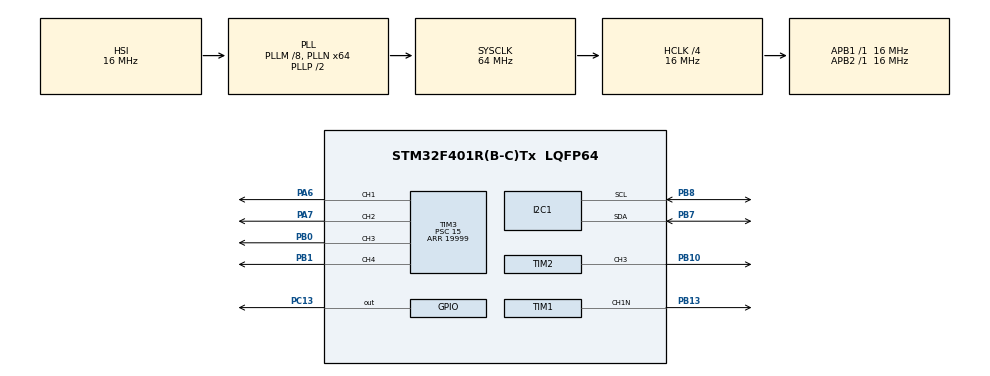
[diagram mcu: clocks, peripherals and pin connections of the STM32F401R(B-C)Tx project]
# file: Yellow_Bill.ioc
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I2C1.OwnAddress=8
Mcu.Family=STM32F4
Mcu.Name=STM32F401R(B-C)Tx
Mcu.Package=LQFP64
NVIC.I2C1_ER_IRQn=true\:0\:0\:false\:false\:true\:true\:true\:true
NVIC.I2C1_EV_IRQn=true\:0\:0\:false\:false\:true\:true\:true\:true
NVIC.PriorityGroup=NVIC_PRIORITYGROUP_4
PA13.Mode=Serial_Wire
PA13.Signal=SYS_JTMS-SWDIO
PA14.Mode=Serial_Wire
PA14.Signal=SYS_JTCK-SWCLK
PA6.Signal=S_TIM3_CH1
PA7.Signal=S_TIM3_CH2
PB0.Signal=S_TIM3_CH3
PB1.Signal=S_TIM3_CH4
PB10.Signal=S_TIM2_CH3
PB13.Mode=PWM Generation1 CH1N
PB13.Signal=TIM1_CH1N
PB7.Mode=I2C
PB7.Signal=I2C1_SDA
PB8.Mode=I2C
PB8.Signal=I2C1_SCL
PC13-ANTI_TAMP.Signal=GPIO_Output
ProjectManager.HeapSize=0x200
ProjectManager.StackSize=0x400
ProjectManager.TargetToolchain=STM32CubeIDE
RCC.48MHZClocksFreq_Value=32000000
RCC.AHBCLKDivider=RCC_SYSCLK_DIV4
RCC.AHBFreq_Value=16000000
RCC.APB1Freq_Value=16000000
RCC.APB1TimFreq_Value=16000000
RCC.APB2Freq_Value=16000000
RCC.APB2TimFreq_Value=16000000
RCC.CortexFreq_Value=16000000
RCC.HCLKFreq_Value=16000000
RCC.HSE_VALUE=25000000
RCC.HSI_VALUE=16000000
RCC.LSE_VALUE=32768
RCC.PLLM=8
RCC.PLLN=64
RCC.SYSCLKFreq_VALUE=64000000
RCC.SYSCLKSource=RCC_SYSCLKSOURCE_PLLCLK
RCC.VCOOutputFreq_Value=128000000
SH.S_TIM2_CH3.0=TIM2_CH3,PWM Generation3 CH3
SH.S_TIM3_CH1.0=TIM3_CH1,PWM Generation1 CH1
SH.S_TIM3_CH2.0=TIM3_CH2,PWM Generation2 CH2
SH.S_TIM3_CH3.0=TIM3_CH3,PWM Generation3 CH3
SH.S_TIM3_CH4.0=TIM3_CH4,PWM Generation4 CH4
TIM1.Channel-PWM\ Generation1\ CH1N=TIM_CHANNEL_1
TIM1.OCFastMode_PWM-PWM\ Generation1\ CH1N=TIM_OCFAST_ENABLE
TIM1.OCNIdleState_1=TIM_OCNIDLESTATE_RESET
TIM1.Period=19999
TIM1.Prescaler=15
TIM2.Channel-PWM\ Generation3\ CH3=TIM_CHANNEL_3
TIM2.Period=19999
TIM2.Prescaler=15
TIM3.Channel-PWM\ Generation1\ CH1=TIM_CHANNEL_1
TIM3.Channel-PWM\ Generation2\ CH2=TIM_CHANNEL_2
TIM3.Channel-PWM\ Generation3\ CH3=TIM_CHANNEL_3
TIM3.Channel-PWM\ Generation4\ CH4=TIM_CHANNEL_4
TIM3.Period=19999
TIM3.Prescaler=15
board=custom

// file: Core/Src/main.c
/* USER CODE BEGIN Header */
/**
  ******************************************************************************
  * @file           : main.c
  * @brief          : Main program body
  ******************************************************************************
  * @attention
  *
  * Copyright (c) 2025 STMicroelectronics.
  * All rights reserved.
  *
  * This software is licensed under terms that can be found in the LICENSE file
  * in the root directory of this software component.
  * If no LICENSE file comes with this software, it is provided AS-IS.
  *
  ******************************************************************************
  */
/* USER CODE END Header */
#include "main.h"

I2C_HandleTypeDef hi2c1;

TIM_HandleTypeDef htim1;
TIM_HandleTypeDef htim2;
TIM_HandleTypeDef htim3;

/* USER CODE BEGIN PV */
uint8_t Channel_Received_Rasp = 0;
uint16_t usPulse_Speed_Received_Rasp = 0;

/* USER CODE END PV */

void SystemClock_Config(void);
static void MX_GPIO_Init(void);
static void MX_TIM3_Init(void);
static void MX_TIM2_Init(void);
static void MX_TIM1_Init(void);
static void MX_I2C1_Init(void);

int main(void)
{

  /* MCU Configuration--------------------------------------------------------*/

  /* Reset of all peripherals, Initializes the Flash interface and the Systick. */
  HAL_Init();

  /* Configure the system clock */
  SystemClock_Config();

  /* Initialize all configured peripherals */
  MX_GPIO_Init();
  MX_TIM3_Init();
  MX_TIM2_Init();
  MX_TIM1_Init();
  MX_I2C1_Init();
  /* USER CODE BEGIN 2 */
//  BLDC_T200_PWM_Init();
//  BLDC_T200_Init();

  if(HAL_I2C_EnableListen_IT(&hi2c1) != HAL_OK){
	  Error_Handler();
  }
  BLDC_T200_PWM_Init();
  BLDC_T200_Init();

  //HAL_I2C_Slave_Receive(&hi2c1, receivedData, 1, HAL_MAX_DELAY);
  /* USER CODE END 2 */

  /* Infinite loop */
  while (1)
  {
	BLDC_T200_SetMotor(Channel_Received_Rasp, usPulse_Speed_Received_Rasp);

  }
}

void SystemClock_Config(void)
{
  RCC_OscInitTypeDef RCC_OscInitStruct = {0};
  RCC_ClkInitTypeDef RCC_ClkInitStruct = {0};

  /** Configure the main internal regulator output voltage
  */
  __HAL_RCC_PWR_CLK_ENABLE();
  __HAL_PWR_VOLTAGESCALING_CONFIG(PWR_REGULATOR_VOLTAGE_SCALE2);

  /** Initializes the RCC Oscillators according to the specified parameters
  * in the RCC_OscInitTypeDef structure.
  */
  RCC_OscInitStruct.OscillatorType = RCC_OSCILLATORTYPE_HSI;
  RCC_OscInitStruct.HSIState = RCC_HSI_ON;
  RCC_OscInitStruct.HSICalibrationValue = RCC_HSICALIBRATION_DEFAULT;
  RCC_OscInitStruct.PLL.PLLState = RCC_PLL_ON;
  RCC_OscInitStruct.PLL.PLLSource = RCC_PLLSOURCE_HSI;
  RCC_OscInitStruct.PLL.PLLM = 8;
  RCC_OscInitStruct.PLL.PLLN = 64;
  RCC_OscInitStruct.PLL.PLLP = RCC_PLLP_DIV2;
  RCC_OscInitStruct.PLL.PLLQ = 4;
  if (HAL_RCC_OscConfig(&RCC_OscInitStruct) != HAL_OK)
  {
    Error_Handler();
  }

  /** Initializes the CPU, AHB and APB buses clocks
  */
  RCC_ClkInitStruct.ClockType = RCC_CLOCKTYPE_HCLK|RCC_CLOCKTYPE_SYSCLK
                              |RCC_CLOCKTYPE_PCLK1|RCC_CLOCKTYPE_PCLK2;
  RCC_ClkInitStruct.SYSCLKSource = RCC_SYSCLKSOURCE_PLLCLK;
  RCC_ClkInitStruct.AHBCLKDivider = RCC_SYSCLK_DIV4;
  RCC_ClkInitStruct.APB1CLKDivider = RCC_HCLK_DIV1;
  RCC_ClkInitStruct.APB2CLKDivider = RCC_HCLK_DIV1;

  if (HAL_RCC_ClockConfig(&RCC_ClkInitStruct, FLASH_LATENCY_0) != HAL_OK)
  {
    Error_Handler();
  }
}

static void MX_I2C1_Init(void)
{

  hi2c1.Instance = I2C1;
  hi2c1.Init.ClockSpeed = 100000;
  hi2c1.Init.DutyCycle = I2C_DUTYCYCLE_2;
  hi2c1.Init.OwnAddress1 = 16;
  hi2c1.Init.AddressingMode = I2C_ADDRESSINGMODE_7BIT;
  hi2c1.Init.DualAddressMode = I2C_DUALADDRESS_DISABLE;
  hi2c1.Init.OwnAddress2 = 0;
  hi2c1.Init.GeneralCallMode = I2C_GENERALCALL_DISABLE;
  hi2c1.Init.NoStretchMode = I2C_NOSTRETCH_DISABLE;
  if (HAL_I2C_Init(&hi2c1) != HAL_OK)
  {
    Error_Handler();
  }

}

static void MX_TIM1_Init(void)
{

  TIM_MasterConfigTypeDef sMasterConfig = {0};
  TIM_OC_InitTypeDef sConfigOC = {0};
  TIM_BreakDeadTimeConfigTypeDef sBreakDeadTimeConfig = {0};

  htim1.Instance = TIM1;
  htim1.Init.Prescaler = 15;
  htim1.Init.CounterMode = TIM_COUNTERMODE_UP;
  htim1.Init.Period = 19999;
  htim1.Init.ClockDivision = TIM_CLOCKDIVISION_DIV1;
  htim1.Init.RepetitionCounter = 0;
  htim1.Init.AutoReloadPreload = TIM_AUTORELOAD_PRELOAD_DISABLE;
  if (HAL_TIM_PWM_Init(&htim1) != HAL_OK)
  {
    Error_Handler();
  }
  sMasterConfig.MasterOutputTrigger = TIM_TRGO_RESET;
  sMasterConfig.MasterSlaveMode = TIM_MASTERSLAVEMODE_DISABLE;
  if (HAL_TIMEx_MasterConfigSynchronization(&htim1, &sMasterConfig) != HAL_OK)
  {
    Error_Handler();
  }
  sConfigOC.OCMode = TIM_OCMODE_PWM1;
  sConfigOC.Pulse = 0;
  sConfigOC.OCPolarity = TIM_OCPOLARITY_HIGH;
  sConfigOC.OCNPolarity = TIM_OCNPOLARITY_HIGH;
  sConfigOC.OCFastMode = TIM_OCFAST_ENABLE;
  sConfigOC.OCIdleState = TIM_OCIDLESTATE_RESET;
  sConfigOC.OCNIdleState = TIM_OCNIDLESTATE_RESET;
  if (HAL_TIM_PWM_ConfigChannel(&htim1, &sConfigOC, TIM_CHANNEL_1) != HAL_OK)
  {
    Error_Handler();
  }
  sBreakDeadTimeConfig.OffStateRunMode = TIM_OSSR_DISABLE;
  sBreakDeadTimeConfig.OffStateIDLEMode = TIM_OSSI_DISABLE;
  sBreakDeadTimeConfig.LockLevel = TIM_LOCKLEVEL_OFF;
  sBreakDeadTimeConfig.DeadTime = 0;
  sBreakDeadTimeConfig.BreakState = TIM_BREAK_DISABLE;
  sBreakDeadTimeConfig.BreakPolarity = TIM_BREAKPOLARITY_HIGH;
  sBreakDeadTimeConfig.AutomaticOutput = TIM_AUTOMATICOUTPUT_DISABLE;
  if (HAL_TIMEx_ConfigBreakDeadTime(&htim1, &sBreakDeadTimeConfig) != HAL_OK)
  {
    Error_Handler();
  }
  HAL_TIM_MspPostInit(&htim1);

}

static void MX_TIM2_Init(void)
{

  TIM_MasterConfigTypeDef sMasterConfig = {0};
  TIM_OC_InitTypeDef sConfigOC = {0};

  htim2.Instance = TIM2;
  htim2.Init.Prescaler = 15;
  htim2.Init.CounterMode = TIM_COUNTERMODE_UP;
  htim2.Init.Period = 19999;
  htim2.Init.ClockDivision = TIM_CLOCKDIVISION_DIV1;
  htim2.Init.AutoReloadPreload = TIM_AUTORELOAD_PRELOAD_DISABLE;
  if (HAL_TIM_PWM_Init(&htim2) != HAL_OK)
  {
    Error_Handler();
  }
  sMasterConfig.MasterOutputTrigger = TIM_TRGO_RESET;
  sMasterConfig.MasterSlaveMode = TIM_MASTERSLAVEMODE_DISABLE;
  if (HAL_TIMEx_MasterConfigSynchronization(&htim2, &sMasterConfig) != HAL_OK)
  {
    Error_Handler();
  }
  sConfigOC.OCMode = TIM_OCMODE_PWM1;
  sConfigOC.Pulse = 0;
  sConfigOC.OCPolarity = TIM_OCPOLARITY_HIGH;
  sConfigOC.OCFastMode = TIM_OCFAST_DISABLE;
  if (HAL_TIM_PWM_ConfigChannel(&htim2, &sConfigOC, TIM_CHANNEL_3) != HAL_OK)
  {
    Error_Handler();
  }
  HAL_TIM_MspPostInit(&htim2);

}

static void MX_TIM3_Init(void)
{

  TIM_MasterConfigTypeDef sMasterConfig = {0};
  TIM_OC_InitTypeDef sConfigOC = {0};

  htim3.Instance = TIM3;
  htim3.Init.Prescaler = 15;
  htim3.Init.CounterMode = TIM_COUNTERMODE_UP;
  htim3.Init.Period = 19999;
  htim3.Init.ClockDivision = TIM_CLOCKDIVISION_DIV1;
  htim3.Init.AutoReloadPreload = TIM_AUTORELOAD_PRELOAD_DISABLE;
  if (HAL_TIM_PWM_Init(&htim3) != HAL_OK)
  {
    Error_Handler();
  }
  sMasterConfig.MasterOutputTrigger = TIM_TRGO_RESET;
  sMasterConfig.MasterSlaveMode = TIM_MASTERSLAVEMODE_DISABLE;
  if (HAL_TIMEx_MasterConfigSynchronization(&htim3, &sMasterConfig) != HAL_OK)
  {
    Error_Handler();
  }
  sConfigOC.OCMode = TIM_OCMODE_PWM1;
  sConfigOC.Pulse = 0;
  sConfigOC.OCPolarity = TIM_OCPOLARITY_HIGH;
  sConfigOC.OCFastMode = TIM_OCFAST_DISABLE;
  if (HAL_TIM_PWM_ConfigChannel(&htim3, &sConfigOC, TIM_CHANNEL_1) != HAL_OK)
  {
    Error_Handler();
  }
  if (HAL_TIM_PWM_ConfigChannel(&htim3, &sConfigOC, TIM_CHANNEL_2) != HAL_OK)
  {
    Error_Handler();
  }
  if (HAL_TIM_PWM_ConfigChannel(&htim3, &sConfigOC, TIM_CHANNEL_3) != HAL_OK)
  {
    Error_Handler();
  }
  if (HAL_TIM_PWM_ConfigChannel(&htim3, &sConfigOC, TIM_CHANNEL_4) != HAL_OK)
  {
    Error_Handler();
  }
  HAL_TIM_MspPostInit(&htim3);

}

static void MX_GPIO_Init(void)
{
  GPIO_InitTypeDef GPIO_InitStruct = {0};

  /* GPIO Ports Clock Enable */
  __HAL_RCC_GPIOC_CLK_ENABLE();
  __HAL_RCC_GPIOA_CLK_ENABLE();
  __HAL_RCC_GPIOB_CLK_ENABLE();

  /*Configure GPIO pin Output Level */
  HAL_GPIO_WritePin(GPIOC, GPIO_PIN_13, GPIO_PIN_RESET);

  /*Configure GPIO pin : PC13 */
  GPIO_InitStruct.Pin = GPIO_PIN_13;
  GPIO_InitStruct.Mode = GPIO_MODE_OUTPUT_PP;
  GPIO_InitStruct.Pull = GPIO_NOPULL;
  GPIO_InitStruct.Speed = GPIO_SPEED_FREQ_LOW;
  HAL_GPIO_Init(GPIOC, &GPIO_InitStruct);

}

void Error_Handler(void)
{
  __disable_irq();
  while (1)
  {
  }
}
